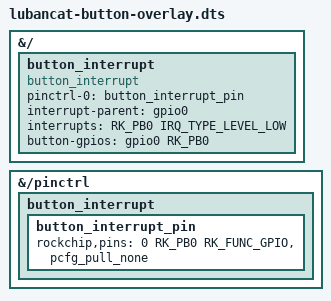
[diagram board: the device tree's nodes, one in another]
/dts-v1/;
/plugin/;

#include <dt-bindings/gpio/gpio.h>
#include <dt-bindings/pinctrl/rockchip.h>
#include <dt-bindings/interrupt-controller/irq.h>

&{/} {
    button_interrupt: button_interrupt {
        status = "okay";
        compatible = "button_interrupt";
        pinctrl-names = "default";
        pinctrl-0 = <&button_interrupt_pin>;
        interrupt-parent = <&gpio0>;
        interrupts = <RK_PB0 IRQ_TYPE_LEVEL_LOW>;
        button-gpios = <&gpio0 RK_PB0 GPIO_ACTIVE_HIGH>;
    };
};

&{/pinctrl} {
    button_interrupt {
        button_interrupt_pin: button_interrupt_pin {
            rockchip,pins = <0 RK_PB0 RK_FUNC_GPIO &pcfg_pull_none>;
        };
    };
};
